# TM4C123GH6PM register map
Vendor: Texas Instruments; Series: TM4C; File version: 11073
CPU: CM4 r1p2, little endian, MPU, FPU, 3 interrupt priority bits
Registers are 32-bit, read-write, reset 0x1 unless marked. A register's access mark holds for its fields unless they carry their own. Offsets are from the block's base; [hi:lo] are bit positions; {n}, {i} and the like mark numbered series.

## FLASH_CTRL — Register map for FLASH_CTRL peripheral
Base 0x400FD000; register names take the prefix FLASH_CTRL
0x00 FMA (reset mask 0x0) — Flash Memory Address
  [17:0] FLASH_FMA_OFFSET — Address Offset
0x04 FMD (reset mask 0x0) — Flash Memory Data
  [31:0] FLASH_FMD_DATA — Data Value
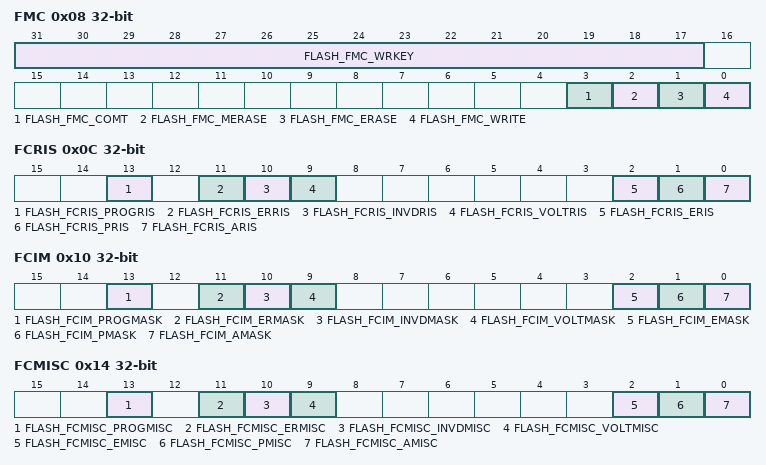
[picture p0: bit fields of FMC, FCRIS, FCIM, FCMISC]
0x08 FMC (reset mask 0x0) — Flash Memory Control
  [31:17] FLASH_FMC_WRKEY — FLASH write key
  [3] FLASH_FMC_COMT — Commit Register Value
  [2] FLASH_FMC_MERASE — Mass Erase Flash Memory
  [1] FLASH_FMC_ERASE — Erase a Page of Flash Memory
  [0] FLASH_FMC_WRITE — Write a Word into Flash Memory
0x0C FCRIS (reset mask 0x0) — Flash Controller Raw Interrupt Status
  [13] FLASH_FCRIS_PROGRIS — PROGVER Raw Interrupt Status
  [11] FLASH_FCRIS_ERRIS — ERVER Raw Interrupt Status
  [10] FLASH_FCRIS_INVDRIS — Invalid Data Raw Interrupt Status
  [9] FLASH_FCRIS_VOLTRIS — VOLTSTAT Raw Interrupt Status
  [2] FLASH_FCRIS_ERIS — EEPROM Raw Interrupt Status
  [1] FLASH_FCRIS_PRIS — Programming Raw Interrupt Status
  [0] FLASH_FCRIS_ARIS — Access Raw Interrupt Status
0x10 FCIM (reset mask 0x0) — Flash Controller Interrupt Mask
  [13] FLASH_FCIM_PROGMASK — PROGVER Interrupt Mask
  [11] FLASH_FCIM_ERMASK — ERVER Interrupt Mask
  [10] FLASH_FCIM_INVDMASK — Invalid Data Interrupt Mask
  [9] FLASH_FCIM_VOLTMASK — VOLT Interrupt Mask
  [2] FLASH_FCIM_EMASK — EEPROM Interrupt Mask
  [1] FLASH_FCIM_PMASK — Programming Interrupt Mask
  [0] FLASH_FCIM_AMASK — Access Interrupt Mask
0x14 FCMISC (reset mask 0x0) — Flash Controller Masked Interrupt Status and Clear
  [13] FLASH_FCMISC_PROGMISC — PROGVER Masked Interrupt Status and Clear
  [11] FLASH_FCMISC_ERMISC — ERVER Masked Interrupt Status and Clear
  [10] FLASH_FCMISC_INVDMISC — Invalid Data Masked Interrupt Status and Clear
  [9] FLASH_FCMISC_VOLTMISC — VOLT Masked Interrupt Status and Clear
  [2] FLASH_FCMISC_EMISC — EEPROM Masked Interrupt Status and Clear
  [1] FLASH_FCMISC_PMISC — Programming Masked Interrupt Status and Clear
  [0] FLASH_FCMISC_AMISC — Access Masked Interrupt Status and Clear
0x20 FMC2 (reset mask 0x0) — Flash Memory Control 2
  [0] FLASH_FMC2_WRBUF — Buffered Flash Memory Write
0x30 FWBVAL (reset mask 0x0) — Flash Write Buffer Valid
  [31:0] FLASH_FWBVAL_FWB — Flash Memory Write Buffer
0x100 FWBN (reset mask 0x0) — Flash Write Buffer n
  [31:0] FLASH_FWBN_DATA — Data
0xFC0 FSIZE (reset mask 0x0) — Flash Size
  [15:0] FLASH_FSIZE_SIZE
    3=FLASH_FSIZE_SIZE_8KB (8 KB of Flash); 7=FLASH_FSIZE_SIZE_16KB (16 KB of Flash); 15=FLASH_FSIZE_SIZE_32KB (32 KB of Flash); 31=FLASH_FSIZE_SIZE_64KB (64 KB of Flash); 47=FLASH_FSIZE_SIZE_96KB (96 KB of Flash); 63=FLASH_FSIZE_SIZE_128KB (128 KB of Flash); 95=FLASH_FSIZE_SIZE_192KB (192 KB of Flash); 127=FLASH_FSIZE_SIZE_256KB (256 KB of Flash)
0xFC4 SSIZE (reset mask 0x0) — SRAM Size
  [15:0] FLASH_SSIZE_SIZE
    7=FLASH_SSIZE_SIZE_2KB (2 KB of SRAM); 15=FLASH_SSIZE_SIZE_4KB (4 KB of SRAM); 23=FLASH_SSIZE_SIZE_6KB (6 KB of SRAM); 31=FLASH_SSIZE_SIZE_8KB (8 KB of SRAM); 47=FLASH_SSIZE_SIZE_12KB (12 KB of SRAM); 63=FLASH_SSIZE_SIZE_16KB (16 KB of SRAM); 79=FLASH_SSIZE_SIZE_20KB (20 KB of SRAM); 95=FLASH_SSIZE_SIZE_24KB (24 KB of SRAM); 127=FLASH_SSIZE_SIZE_32KB (32 KB of SRAM)
0xFCC ROMSWMAP (reset mask 0x0) — ROM Software Map
0xFCC ROMSWMAP (reset mask 0x0) (FLASH_CTRL_ALT view) — ROM Software Map
  [0] FLASH_ROMSWMAP_SAFERTOS — SafeRTOS Present
0x10F0 RMCTL (reset mask 0x0) — ROM Control
  [0] FLASH_RMCTL_BA — Boot Alias
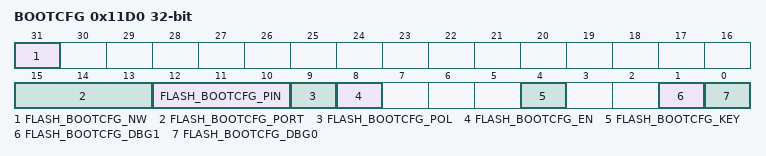
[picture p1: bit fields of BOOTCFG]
0x11D0 BOOTCFG (reset mask 0x0) — Boot Configuration
  [31] FLASH_BOOTCFG_NW — Not Written
  [15:13] FLASH_BOOTCFG_PORT — Boot GPIO Port
    0=FLASH_BOOTCFG_PORT_A (Port A); 1=FLASH_BOOTCFG_PORT_B (Port B); 2=FLASH_BOOTCFG_PORT_C (Port C); 3=FLASH_BOOTCFG_PORT_D (Port D); 4=FLASH_BOOTCFG_PORT_E (Port E); 5=FLASH_BOOTCFG_PORT_F (Port F); 6=FLASH_BOOTCFG_PORT_G (Port G); 7=FLASH_BOOTCFG_PORT_H (Port H)
  [12:10] FLASH_BOOTCFG_PIN — Boot GPIO Pin
    {v}=Pin {v} (v=0..7)
  [9] FLASH_BOOTCFG_POL — Boot GPIO Polarity
  [8] FLASH_BOOTCFG_EN — Boot GPIO Enable
  [4] FLASH_BOOTCFG_KEY — KEY Select
  [1] FLASH_BOOTCFG_DBG1 — Debug Control 1
  [0] FLASH_BOOTCFG_DBG0 — Debug Control 0
{0x11E0+4i} USERREG{i} (reset mask 0x0) (i=0..3) — User Register {i}
  [31:0] FLASH_USERREG{i}_DATA — User Data
{0x1200+4i} FMPRE{i} (reset mask 0x0) (i=0..3) — Flash Memory Protection Read Enable {i}
{0x1400+4i} FMPPE{i} (reset mask 0x0) (i=0..3) — Flash Memory Protection Program Enable {i}
